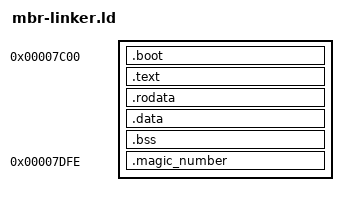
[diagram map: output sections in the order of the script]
ENTRY(_start)

SECTIONS {
    . = 0x7c00;
    .boot :
    {
        *(.boot .boot.*)
    }
    .text :
    {
        *(.text .text.*)
    }
    .rodata :
    {
        *(.rodata .rodata.*)
    }
    .data :
    {
        *(.rodata .rodata.*)
        *(.data .data.*)
        *(.got .got.*)
    }
    .bss :
    {
         *(.bss .bss.*)
    }

    . = 0x7c00 + 510;

    .magic_number :
    {
        SHORT(0xaa55)       /* magic number for bootable disk */
    }
}
